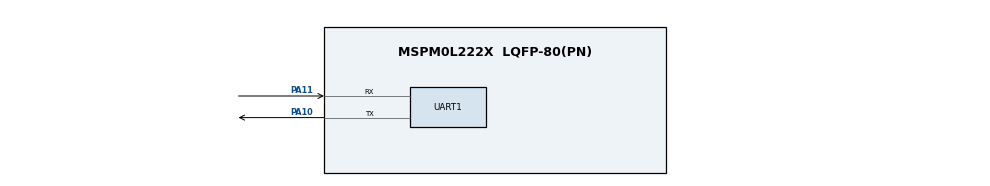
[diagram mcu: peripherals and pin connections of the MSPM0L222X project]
/**
 * @cliArgs --device "MSPM0L222X" --part "Default" --package "LQFP-80(PN)" --product "mspm0_sdk@2.11.00.07"
 * @versions {"tool":"1.26.2+4477"}
 */

/**
 * Import the modules used in this configuration.
 */
const AESADV        = scripting.addModule("/ti/driverlib/AESADV");
const GPIO          = scripting.addModule("/ti/driverlib/GPIO", {}, false);
const GPIO1         = GPIO.addInstance();
const SYSCTL        = scripting.addModule("/ti/driverlib/SYSCTL");
const UART          = scripting.addModule("/ti/driverlib/UART", {}, false);
const UART1         = UART.addInstance();
const ProjectConfig = scripting.addModule("/ti/project_config/ProjectConfig");

/**
 * Write custom configuration values to the imported modules.
 */
const Board = scripting.addModule("/ti/driverlib/Board", {}, false);

GPIO1.$name                   = "GPIO_TRIG";
GPIO1.associatedPins[0].$name = "PIN_0";


UART1.$name                    = "UART_1";
UART1.targetBaudRate           = 115200;
UART1.peripheral.$assign       = "UART0";
UART1.peripheral.rxPin.$assign = "PA11";
UART1.peripheral.txPin.$assign = "PA10";
UART1.txPinConfig.$name        = "ti_driverlib_gpio_GPIOPinGeneric2";
UART1.rxPinConfig.$name        = "ti_driverlib_gpio_GPIOPinGeneric3";

ProjectConfig.deviceSpin = "MSPM0L2228";

/**
 * Pinmux solution for unlocked pins/peripherals. This ensures that minor changes to the automatic solver in a future
 * version of the tool will not impact the pinmux you originally saw.  These lines can be completely deleted in order to
 * re-solve from scratch.
 */
Board.peripheral.$suggestSolution            = "DEBUGSS";
Board.peripheral.swclkPin.$suggestSolution   = "PA20";
Board.peripheral.swdioPin.$suggestSolution   = "PA19";
GPIO1.associatedPins[0].pin.$suggestSolution = "PA0";
SYSCTL.peripheral.$suggestSolution           = "SYSCTL";
